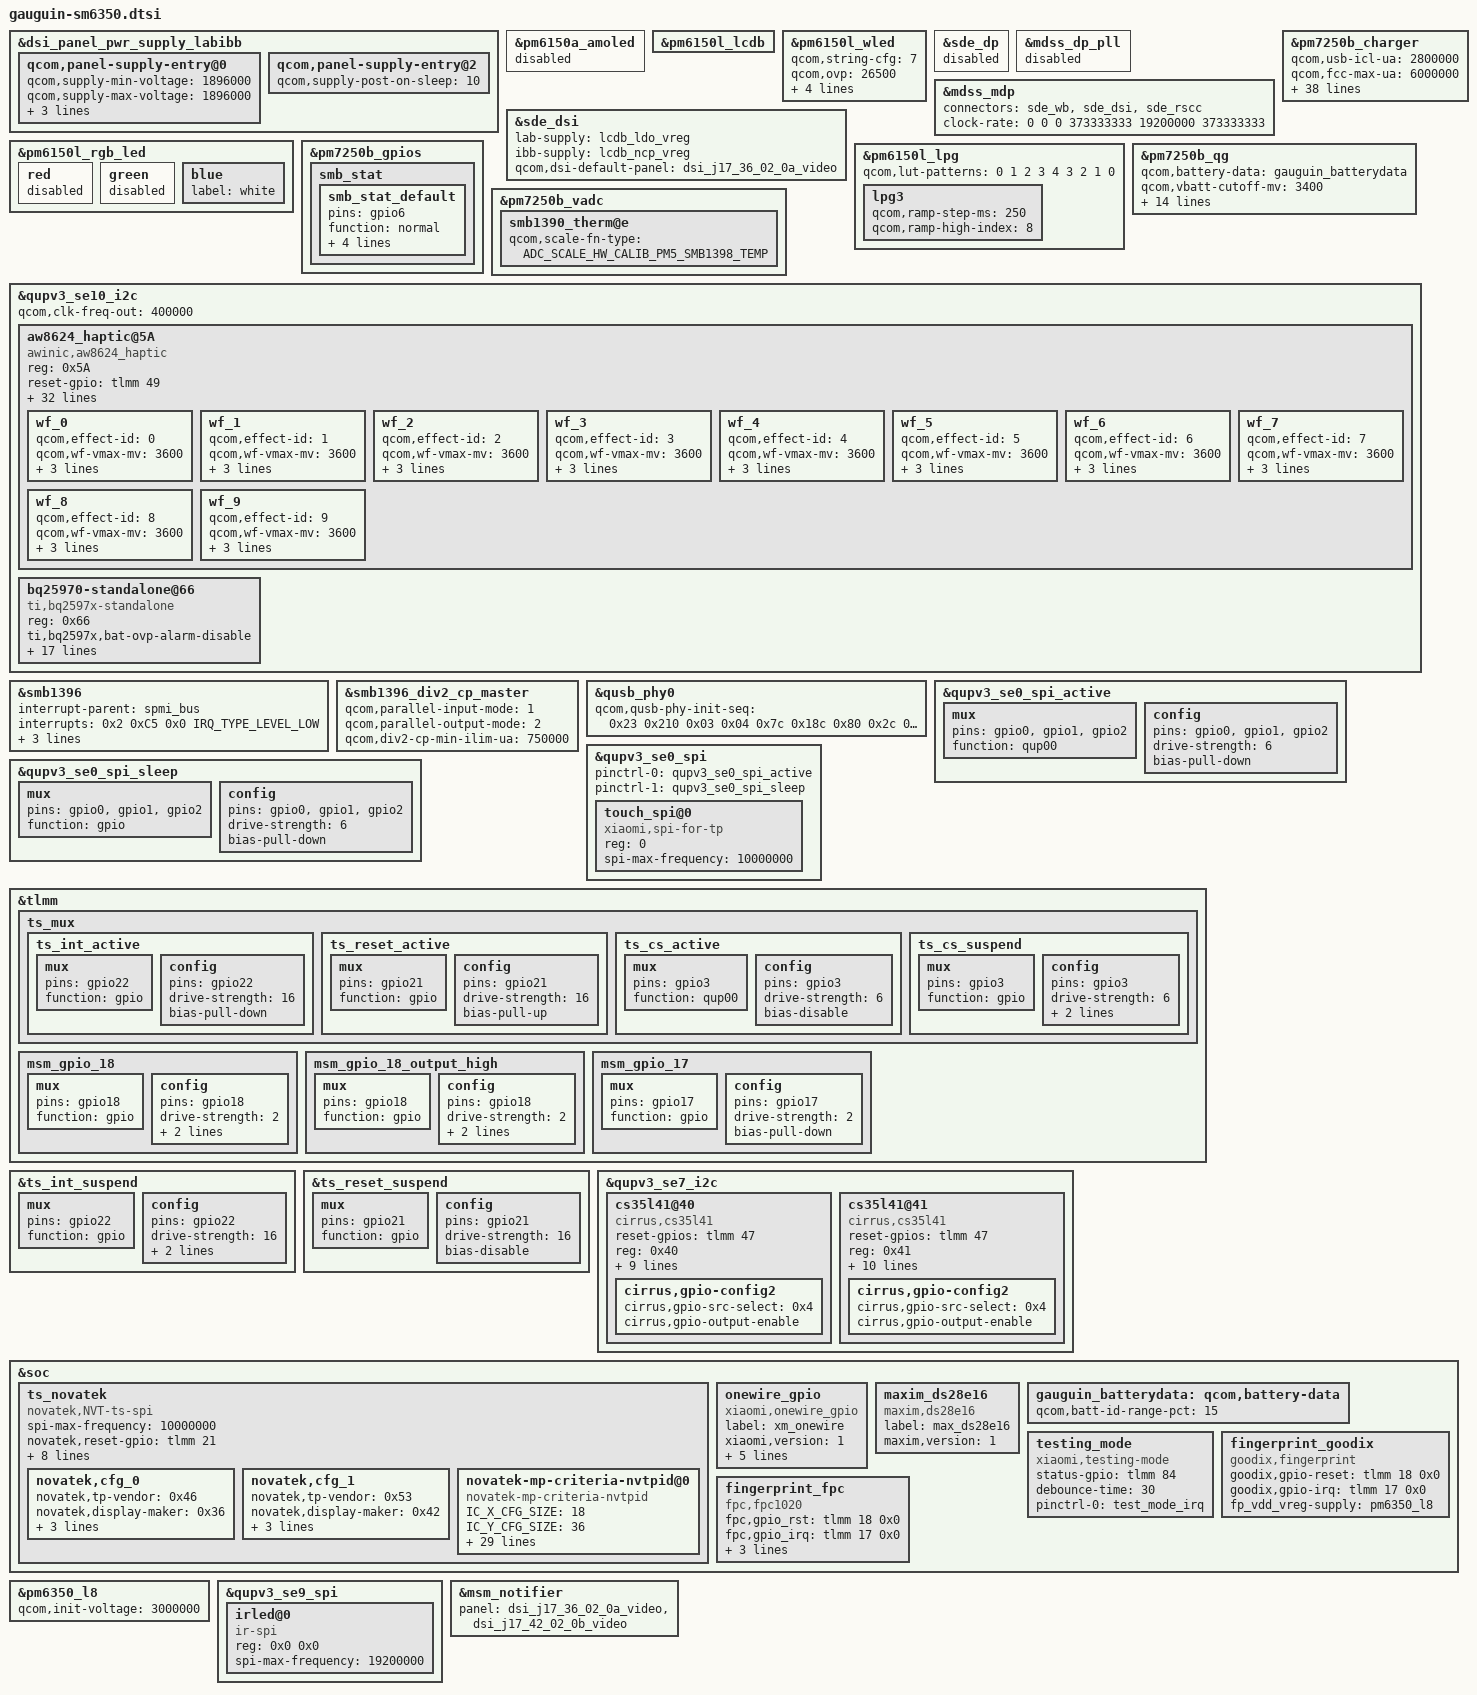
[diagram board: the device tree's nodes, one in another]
 /*
 file is for attribution only of gauguin
 And public attribution of xiaomi platforms(like J17 and so and)
 */

#include "gauguin-pinctrl.dtsi"
#include "xiaomi-sm6350-common.dtsi"
#include "gauguin-audio-overlay.dtsi"
#include <dt-bindings/pinctrl/qcom,pmic-gpio.h>
#include <dt-bindings/iio/qcom,spmi-vadc.h>

&dsi_panel_pwr_supply_labibb {
	qcom,panel-supply-entry@0 {
		qcom,supply-min-voltage = <1896000>;
		qcom,supply-max-voltage = <1896000>;
		qcom,supply-post-on-sleep = <1>;
		qcom,supply-post-off-sleep = <20>;
		qcom,supply-pre-off-sleep = <5>;
	};

	qcom,panel-supply-entry@2 {
		qcom,supply-post-on-sleep = <10>;
	};
};

&pm6150a_amoled {
	status = "disabled";
};

&pm6150l_lcdb {
	status = "ok";
	/delete-property/ qcom,voltage-step-ramp;
};

&pm6150l_wled {
	status = "ok";
	qcom,string-cfg = <7>;
	qcom,ovp = <26500>;
	qcom,fs-current-limit = <25000>;
	qcom,cabc-sel = <1>;
	mi,cabcoff-dbv = <200>;
	mi,cabc-pwm = <3111 4095>;
};

&sde_dp {
	status = "disabled";
};

&mdss_dp_pll {
	status = "disabled";
};

&mdss_mdp {
	connectors = <&sde_wb &sde_dsi &sde_rscc>;
	clock-rate = <0 0 0 373333333 19200000 373333333>;
};

&sde_dsi {
	/delete-property/ vdd-supply;
	lab-supply = <&lcdb_ldo_vreg>;
	ibb-supply = <&lcdb_ncp_vreg>;
	qcom,dsi-default-panel = <&dsi_j17_36_02_0a_video>;
};

&pm6150l_rgb_led {
	red {
		status = "disabled";
	};

	green {
		status = "disabled";
	};

	blue {
		label = "white";
	};
};

&pm6150l_lpg {
	qcom,lut-patterns = <0 1 2 3 4
				3 2 1 0>;
	lpg3 {
		qcom,ramp-step-ms = <250>;
		qcom,ramp-high-index = <8>;
	};
};

&pm7250b_charger {
	status = "ok";
	qcom,usb-icl-ua = <2800000>;
	qcom,fcc-max-ua = <6000000>;
	qcom,fv-max-uv = <4470000>;
	qcom,non-fcc-fv-max-uv = <4450000>;
	qcom,float-option = <1>;
	qcom,chg-term-src = <1>;
	qcom,chg-term-current-ma = <(-220)>;
	qcom,auto-recharge-soc = <99>;
	//qcom,step-charging-enable;
	qcom,sw-jeita-enable;
	qcom,lpd-disable;
	qcom,support-conn-therm;
	qcom,battery-data = <&gauguin_batterydata>;
	vbus-disable-gpio = <&tlmm 71 GPIO_ACTIVE_HIGH>;
	pinctrl-names = "default", "vbus_disable_active", "vbus_disable_suspend";
	pinctrl-0 = <&vbus_disable_suspend>;
	pinctrl-1 = <&vbus_disable_active>;
	pinctrl-2 = <&vbus_disable_suspend>;
	qcom,distinguish-qc-class-ab;
	mi,six-pin-step-chg-params = <4200000  6000000
				4400000  5400000
				4470000  3776000>;
	mi,six-pin-step-chg;
	mi,six-pin-soc-th = <10>;
	mi,support-ffc;
	qcom,thermal-mitigation = <3000000 2800000 2600000 2400000 2200000 2100000 2000000
			                           1800000 1600000 1500000 1400000 1200000 1000000 900000
			                           800000 500000>;
	qcom,thermal-mitigation-icl = <2800000 2700000 2600000 2400000 2200000 2100000 2000000
			                           1800000 1600000 1500000 1400000 1300000 1200000 1100000
			                           950000 750000>;
	qcom,thermal-mitigation-dcp = <3000000 2800000 2600000 2400000 2200000 2100000 2000000
			                           1800000 1600000 1500000 1400000 1200000 1000000 900000
			                           800000 500000>;
	qcom,thermal-mitigation-qc2 = <4800000 4600000 4400000 4100000 3900000 3600000 3000000
			                           2600000 2000000 1500000 1400000 1200000 1000000 900000
			                           800000 500000>;
	qcom,thermal-fcc-qc3p5 = <4500000 4400000 4200000 4100000 4000000 3800000 3600000
			                           3400000 3200000 3000000 2800000 2400000 2000000 1000000
			                           750000 750000>;
	qcom,thermal-fcc-qc3-cp = <3600000 3500000 3400000 3300000 3200000 3100000 3000000
			                           2900000 2800000 2600000 2400000 2200000 2000000 2000000
			                           750000 700000>;
	qcom,thermal-fcc-qc3-classb-cp = <5000000 4800000 4600000 4400000 4200000 4000000 3800000
			                           3600000 3400000 3200000 2500000 2200000 2000000 1300000
			                           1000000 700000>;
	qcom,thermal-mitigation-pd-base = <4800000 4500000 4200000 4100000 4000000 3800000 3600000
							3400000 3200000 3000000 2800000 2400000 2000000 1000000
							750000 750000>;
	qcom,thermal-fcc-pps = <6000000 5700000 5400000 5200000 4800000 4600000 4400000
							4200000 3800000 3400000 3000000 2600000 2000000 1000000
				   			700000 500000>;

};

&pm7250b_qg {
	qcom,battery-data = <&gauguin_batterydata>;
	qcom,vbatt-cutoff-mv = <3400>;
	qcom,vbatt-low-mv = <3300>;
	qcom,vbatt-empty-mv = <3100>;
	qcom,fvss-vbatt-mv = <3600>;
	qcom,s3-entry-fifo-length = <2>;
	qcom,s3-entry-ibat-ua = <25000>;
	qcom,s3-exit-ibat-ua = <45000>;
	qcom,qg-iterm-ma = <1200>;
	qcom,fvss-enable;
	qcom,qg-ext-sns;
	qcom,batterysecret-support;
	qcom,shutdown-delay-enable;
	qcom,soc_decimal_rate = <
		0  32
		10 30
		20 28
		30 28
		40 28
		50 28
		60 28
		70 28
		80 28
		90 26
		95 10
		99 5>;
	qcom,qg-fast-chg-config;
};

&pm7250b_gpios {
	smb_stat {
		smb_stat_default: smb_stat_default {
			pins = "gpio6";
			function = "normal";
			input-enable;
			bias-pull-up;
			qcom,pull-up-strength = <PMIC_GPIO_PULL_UP_30>;
			power-source = <0>;
		};
	};
};

&pm7250b_vadc {
	smb1390_therm@e {
		qcom,scale-fn-type = <ADC_SCALE_HW_CALIB_PM5_SMB1398_TEMP>;
	};
};

&qupv3_se10_i2c {
	status = "ok";
	qcom,clk-freq-out = <400000>;
	#include "smb1398.dtsi"
	aw8624_haptic@5A {
		compatible = "awinic,aw8624_haptic";
		reg = <0x5A>;
		reset-gpio = <&tlmm 49 0>;
		irq-gpio = <&tlmm 53 0>;
		vib_f0_pre = < 2050 >;
		vib_f0_cali_percen = < 7 >;
		vib_cont_drv_lev = < 106 >;
		vib_cont_drv_lvl_ov = < 155 >;
		vib_cont_td = < 0xF06C >;
		vib_cont_zc_thr = < 0x08F8 >;
		vib_cont_num_brk = < 3 >;
		vib_f0_coeff = < 260 >; /*Don't modify it*/
		vib_duration_time = < 15 60 0 0 0 >;
		vib_brake_ram_config = < 1 1 90 60 20 3 1 3 1 1 90 60 30 5 1 3 0 0 50 40 25 0 5 3 >;
		vib_brake_cont_config = < 1 1 90 42 20 5 2 2 0 0 0 0 0 0 0 0 0 0 0 0 0 0 0 0 >;
		vib_f0_trace_parameter = < 9 5 1 15 >;
		vib_bemf_config = < 0 8 3 0xf8 >;
		vib_sw_brake = < 0x2c >;
		vib_wavseq = < 0 1 1 2 0 0 0 0 0 0 0 0 0 0 0 0 >; /*wavseq1-seq8 0x07-0x0E*/
		vib_wavloop = < 0 6 1 15 0 0 0 0 0 0>;/*loop1-mainloog 0x0f-0x13*/
		vib_td_brake = < 42720 42720 42720 >; /*level0 level1 level2*/
		vib_tset = < 0x11 >;
		vib_func_parameter1 = < 1 >;
		vib_gain_flag = < 1 >;
		vib_r_spare = < 0x68 >;
		vib_bstdbg = < 0x30 0xeb 0xd4 0 0 0 >;
		vib_effect_id_boundary = < 10 >;
		vib_effect_max = < 170 >;
		vib_rtp_time = < 20 20 20 20 20 20 20 20 20 30
				 40 50 60 70 80 90 100 110 120 130
				 140 150 160 170 180 190 200 210 220 230
				 240 250 260 270 280 290 300 310 320 330
				 20 20 20 20 20 20 20 20 20 20
				 20 20 20 20 20 20 20 20 20 20
				 20 20 20 20 20 20 20 20 20 20
				 20 20 20 20 20 20 20 20 20 20
				 20 20 20 20 20 20 20 20 20 20
				 20 20 20 20 20 20 20 20 20 20
				 20 20 20 20 20 20 20 20 20 20
				 20 20 20 20 20 20 20 20 20 20
				 20 20 20 20 20 20 20 20 20 20
				 20 20 20 20 20 20 20 20 20 20
				 20 20 20 20 20 20 20 20 20 20
				 20 20 20 20 20 20 20 20 20 20
				 20 20 20 20 20 20 20 20 20 20
				 20 20 20 20 20 >;
		pinctrl-names = "aw8624_reset_reset","aw8624_reset_active","aw8624_interrupt_active";
		pinctrl-0 = <&aw8624_gpio_reset>;
		pinctrl-1 = <&aw8624_gpio_reset_output_high>;
		pinctrl-2 = <&aw8624_gpio_interrupt>;
		wf_0 {
			/*CLICK*/
			qcom,effect-id = <0>;
			qcom,wf-vmax-mv = <3600>;
			qcom,wf-pattern = [3e 3e];
			qcom,wf-brake-pattern = [02 01 00 00];
			qcom,wf-play-rate-us = <20000>;
		};
		wf_1 {
			/*DOUBLE CLICK*/
			qcom,effect-id = <1>;
			qcom,wf-vmax-mv = <3600>;
			qcom,wf-pattern = [7e 3e];
			qcom,wf-brake-pattern = [03 01 00 00];
			qcom,wf-play-rate-us = <20000>;
		};
		wf_2 {
			/*TICK*/
			qcom,effect-id = <2>;
			qcom,wf-vmax-mv = <3600>;
			qcom,wf-pattern = [7e 3e];
			qcom,wf-brake-pattern = [02 01 00 00];
			qcom,wf-play-rate-us = <20000>;
		};
		wf_3 {
			/*THUD*/
			qcom,effect-id = <3>;
			qcom,wf-vmax-mv = <3600>;
			qcom,wf-pattern = [3e 3e];
			qcom,wf-brake-pattern = [02 01 00 00];
			qcom,wf-play-rate-us = <20000>;
		};
		wf_4 {
			/*POP*/
			qcom,effect-id = <4>;
			qcom,wf-vmax-mv = <3600>;
			qcom,wf-pattern = [3e 3e];
			qcom,wf-brake-pattern = [02 01 00 00];
			qcom,wf-play-rate-us = <28000>;
		};
		wf_5 {
			/*HEAVY CLICK*/
			qcom,effect-id = <5>;
			qcom,wf-vmax-mv = <3600>;
			qcom,wf-pattern = [7e 7e 7e];
			qcom,wf-brake-pattern = [03 03 01 00];
			qcom,wf-play-rate-us = <20000>;
		};
		wf_6 {
			/*id 6*/
			qcom,effect-id = <6>;
			qcom,wf-vmax-mv = <3600>;
			qcom,wf-pattern = [3e 3e];
			qcom,wf-brake-pattern = [02 01 00 00];
			qcom,wf-play-rate-us = <20000>;
		};
		wf_7 {
			/*id 7*/
			qcom,effect-id = <7>;
			qcom,wf-vmax-mv = <3600>;
			qcom,wf-pattern = [3e 3e];
			qcom,wf-brake-pattern = [02 01 00 00];
			qcom,wf-play-rate-us = <20000>;
		};
		wf_8 {
			/*id 8*/
			qcom,effect-id = <8>;
			qcom,wf-vmax-mv = <3600>;
			qcom,wf-pattern = [3e 3e];
			qcom,wf-brake-pattern = [02 01 00 00];
			qcom,wf-play-rate-us = <20000>;
		};
		wf_9 {
			/*id 9*/
			qcom,effect-id = <9>;
			qcom,wf-vmax-mv = <3600>;
			qcom,wf-pattern = [3e 3e];
			qcom,wf-brake-pattern = [02 01 00 00];
			qcom,wf-play-rate-us = <20000>;
		};
	};
	/* AWINIC AW8624 Haptic End */

	bq25970-standalone@66 {
		compatible = "ti,bq2597x-standalone";
		reg = <0x66>;
		/*interrupt-parent = <&tlmm>;
		interrupts = <157 0x2002>;
		pinctrl-names = "default";
		pinctrl-0 = <&bq2597x_master_int_default>;*/

		/*ti,bq2597x,bat-ovp-disable;*/
		ti,bq2597x,bat-ovp-alarm-disable;
		ti,bq2597x,bat-ocp-disable;
		ti,bq2597x,bat-ocp-alarm-disable;
		ti,bq2597x,bat-ucp-alarm-disable;
		ti,bq2597x,bat-ucp-disable;

		/*ti,bq2597x,bus-ovp-alarm-disable;
		ti,bq2597x,bus-ocp-disable;
		ti,bq2597x,bus-ocp-alarm-disable;*/
		ti,bq2597x,bat-therm-disable;
		ti,bq2597x,bus-therm-disable;
		ti,bq2597x,die-therm-disable;

		ti,bq2597x,bat-ovp-threshold = <4525>;
		ti,bq2597x,bat-ovp-alarm-threshold = <4525>;
		//ti,bq2597x,bat-ocp-threshold = <8000>;
		//ti,bq2597x,bat-ocp-alarm-threshold = <7500>;

		ti,bq2597x,bus-ovp-threshold = <12000>;
		ti,bq2597x,bus-ovp-alarm-threshold = <11000>;
		ti,bq2597x,bus-ocp-threshold = <3750>;
		ti,bq2597x,bus-ocp-alarm-threshold = <3500>;

		//ti,bq2597x,bat-ucp-alarm-threshold = <2000>;

		ti,bq2597x,bat-therm-threshold = <0x15>;/*4.1%*/
		ti,bq2597x,bus-therm-threshold = <0x15>;/*4.1%*/
		ti,bq2597x,die-therm-threshold = <145>;

		ti,bq2597x,ac-ovp-threshold = <14>;
		//ti,bq2597x,sense-resistor-mohm = <2>;
	};
};

&smb1396 {
	interrupt-parent = <&spmi_bus>;
	interrupts = <0x2 0xC5 0x0 IRQ_TYPE_LEVEL_LOW>;
	interrupt_names = "smb1396";
	pinctrl-names = "default";
	pinctrl-0 = <&smb_stat_default>;
	qcom,enable-toggle-stat;
	status = "ok";
};

&smb1396_div2_cp_master {
	qcom,parallel-input-mode = <1>; /* USBIN */
	qcom,parallel-output-mode = <2>; /* VBAT */
	qcom,div2-cp-min-ilim-ua = <750000>;
	status = "ok";
};

&qusb_phy0 {
	qcom,qusb-phy-init-seq =
			/* <value reg_offset> */
			<0x23 0x210 /* PWR_CTRL1 */
			 0x03 0x04  /* PLL_ANALOG_CONTROLS_TWO */
			 0x7c 0x18c /* PLL_CLOCK_INVERTERS */
			 0x80 0x2c  /* PLL_CMODE */
			 0x0a 0x184 /* PLL_LOCK_DELAY */
			 0x19 0xb4  /* PLL_DIGITAL_TIMERS_TWO */
			 0x40 0x194 /* PLL_BIAS_CONTROL_1 */
			 0x17 0x198 /* PLL_BIAS_CONTROL_2 */
			 0x21 0x214 /* PWR_CTRL2 */
			 0x08 0x220 /* IMP_CTRL1 */
			 0x58 0x224 /* IMP_CTRL2 */
			 0x47 0x240 /* TUNE1 */
			 0x29 0x244 /* TUNE2 */
			 0xca 0x248 /* TUNE3 */
			 0x02 0x24c /* TUNE4 */
			 0x03 0x250 /* TUNE5 */
			 0x30 0x23c /* CHG_CTRL2 */
			 0x22 0x210>; /* PWR_CTRL1 */
};

/*Touch SPI state init*/
&qupv3_se0_spi_active {
	mux {
		pins = "gpio0", "gpio1", "gpio2";
		function = "qup00";
	};

	config {
		pins = "gpio0", "gpio1", "gpio2";
		drive-strength = <6>;
		bias-pull-down;
	};
};

&qupv3_se0_spi_sleep {
	mux {
		pins = "gpio0", "gpio1", "gpio2";
		function = "gpio";
	};

	config {
		pins = "gpio0", "gpio1", "gpio2";
		drive-strength = <6>;
		bias-pull-down;
	};
};

&qupv3_se0_spi {
	pinctrl-0 = <&qupv3_se0_spi_active>;
	pinctrl-1 = <&qupv3_se0_spi_sleep>;
};

/*IC int pin, rst pin init*/
&tlmm {
	ts_mux {
		ts_int_active: ts_int_active {
			mux {
				pins = "gpio22";
				function = "gpio";
			};

			config {
				pins = "gpio22";
				drive-strength = <16>;
				bias-pull-down;
			};
		};

		ts_reset_active: ts_reset_active {
			mux {
				pins = "gpio21";
				function = "gpio";
			};

			config {
				pins = "gpio21";
				drive-strength = <16>;
				bias-pull-up;
			};
		};

		ts_cs_active: ts_cs_active {
			mux {
				pins = "gpio3";
				function = "qup00";
			};

			config {
				pins = "gpio3";
				drive-strength = <6>;
				bias-disable;
			};
		};

		ts_cs_suspend: ts_cs_suspend {
			mux {
				pins = "gpio3";
				function = "gpio";
			};

			config {
				pins = "gpio3";
				drive-strength = <6>;
				bias-pull-down;
				output-low;
			};
		};
	};
};

&ts_int_suspend {
	mux {
		pins = "gpio22";
		function = "gpio";
	};

	config {
		pins = "gpio22";
		drive-strength = <16>;
		bias-disable;
		input-enable;
	};
};

&ts_reset_suspend {
	mux {
		pins = "gpio21";
		function = "gpio";
	};

	config {
		pins = "gpio21";
		drive-strength = <16>;
		bias-disable;
	};
};

&qupv3_se0_spi {
	status = "ok";
	touch_spi@0 {
		compatible = "xiaomi,spi-for-tp";
		reg = <0>;
		status = "ok";
		spi-max-frequency = <10000000>;  //10M
	};
};

&qupv3_se7_i2c {
	status = "ok";

	/* Speaker */
	cs35l41@40 {
		#sound-dai-cells = <1>;
		compatible = "cirrus,cs35l41";
		reset-gpios = <&tlmm 47 0>;
		reg = <0x40>;
		pinctrl-names = "cs35l41_irq_speaker";
		pinctrl-0 = <&cs35l41_int_speaker>;
		interrupt-parent = <&tlmm>;
		interrupts = <12 8>;
		cirrus,temp-warn_threshold = <3>;
		cirrus,boost-peak-milliamp = <4000>;
		cirrus,boost-ind-nanohenry = <1000>;
		cirrus,boost-cap-microfarad = <15>;
		cirrus,asp-sdout-hiz = <1>;
		cirrus,right-channel-amp;
		cirrus,gpio-config2 {
			cirrus,gpio-src-select = <0x4>;
			cirrus,gpio-output-enable;
		};
	};

	/* Receiver */
	cs35l41@41 {
		#sound-dai-cells = <1>;
		compatible = "cirrus,cs35l41";
		reset-gpios = <&tlmm 47 0>;
		reg = <0x41>;
		pinctrl-names = "cs35l41_irq_speaker_rcv";
		pinctrl-0 = <&cs35l41_int_speaker_rcv>;
		interrupt-parent = <&tlmm>;
		interrupts = <48 8>;
		cirrus,temp-warn_threshold = <3>;
		cirrus,boost-peak-milliamp = <4000>;
		cirrus,boost-ind-nanohenry = <1000>;
		cirrus,boost-cap-microfarad = <15>;
		//cirrus,right-channel-amp;
		cirrus,tuning-has-prefix;
		cirrus,asp-sdout-hiz = <1>;
		sound-name-prefix = "RCV";
		cirrus,gpio-config2 {
			cirrus,gpio-src-select = <0x4>;
			cirrus,gpio-output-enable;
		};
	};
};

/* Novatek device tree node */
&soc {
	ts_novatek {
		compatible = "novatek,NVT-ts-spi";
		status = "ok";
		spi-max-frequency = <10000000>;  /*4800000,9600000,15000000,19200000 10M*/
		novatek,reset-gpio = <&tlmm 21 0x00>;
		novatek,irq-gpio = <&tlmm 22 0x2001>;
		pinctrl-names = "pmx_ts_active", "pmx_ts_suspend";
		pinctrl-0 = <&ts_int_active &ts_reset_active &ts_cs_active>;
		pinctrl-1 = <&ts_int_suspend &ts_reset_suspend &ts_cs_suspend>;
		/* 672 */
		/*novatek,swrst-n8-addr = <0x01F01A>;*/
		/* 672A */
		novatek,swrst-n8-addr = <0x03F0FE>;
		novatek,spi-rd-fast-addr = <0x03F310>;
		novatek,config-array-size = <2>;
		novatek,cfg_0 {
			novatek,tp-vendor = <0x46>;
			novatek,display-maker = <0x36>;
			novatek,fw-name = "novatek_nt36672c_j17_fw01.bin";
			novatek,mp-name = "novatek_nt36672c_j17_mp01.bin";
			novatek,clicknum-file-name = "nvt+tianma";
		};
		novatek,cfg_1 {
			novatek,tp-vendor = <0x53>;
			novatek,display-maker = <0x42>;
			novatek,fw-name = "novatek_nt36672c_j17_fw02.bin";
			novatek,mp-name = "novatek_nt36672c_j17_mp02.bin";
			novatek,clicknum-file-name = "nvt+csot";
		};
		/* MP */
		/*novatek,mp-support-dt;*/
		novatek-mp-criteria-nvtpid@0 {
			#address-cells = <1>;
			#size-cells = <0>;
			compatible = "novatek-mp-criteria-nvtpid";
			/* MP Config */
			IC_X_CFG_SIZE = <18>;
			IC_Y_CFG_SIZE = <36>;
			IC_KEY_CFG_SIZE = <4>;
			X_Channel = <18>;
			Y_Channel = <36>;
			AIN_X = <0 1 2 3 4 5 6 7 8 9 10 11 12 13 14 15 16 17>;
			AIN_Y = <0 1 2 3 4 5 6 7 8 9 10 11 12 13 14 15 16 17
						18 19 20 21 22 23 24 25 26 27 28 29 30 31 32 33 34 35>;
			AIN_KEY = <0 1 2 0xFF>;
			/* MP Criteria */
			PS_Config_Lmt_Short_Rawdata_P = <
				14008 14008 14008 14008 14008 14008 14008 14008 14008 14008 14008 14008 14008 14008 14008 14008 14008 14008
				14008 14008 14008 14008 14008 14008 14008 14008 14008 14008 14008 14008 14008 14008 14008 14008 14008 14008
				14008 14008 14008 14008 14008 14008 14008 14008 14008 14008 14008 14008 14008 14008 14008 14008 14008 14008
				14008 14008 14008 14008 14008 14008 14008 14008 14008 14008 14008 14008 14008 14008 14008 14008 14008 14008
				14008 14008 14008 14008 14008 14008 14008 14008 14008 14008 14008 14008 14008 14008 14008 14008 14008 14008
				14008 14008 14008 14008 14008 14008 14008 14008 14008 14008 14008 14008 14008 14008 14008 14008 14008 14008
				14008 14008 14008 14008 14008 14008 14008 14008 14008 14008 14008 14008 14008 14008 14008 14008 14008 14008
				14008 14008 14008 14008 14008 14008 14008 14008 14008 14008 14008 14008 14008 14008 14008 14008 14008 14008
				14008 14008 14008 14008 14008 14008 14008 14008 14008 14008 14008 14008 14008 14008 14008 14008 14008 14008
				14008 14008 14008 14008 14008 14008 14008 14008 14008 14008 14008 14008 14008 14008 14008 14008 14008 14008
				14008 14008 14008 14008 14008 14008 14008 14008 14008 14008 14008 14008 14008 14008 14008 14008 14008 14008
				14008 14008 14008 14008 14008 14008 14008 14008 14008 14008 14008 14008 14008 14008 14008 14008 14008 14008
				14008 14008 14008 14008 14008 14008 14008 14008 14008 14008 14008 14008 14008 14008 14008 14008 14008 14008
				14008 14008 14008 14008 14008 14008 14008 14008 14008 14008 14008 14008 14008 14008 14008 14008 14008 14008
				14008 14008 14008 14008 14008 14008 14008 14008 14008 14008 14008 14008 14008 14008 14008 14008 14008 14008
				14008 14008 14008 14008 14008 14008 14008 14008 14008 14008 14008 14008 14008 14008 14008 14008 14008 14008
				14008 14008 14008 14008 14008 14008 14008 14008 14008 14008 14008 14008 14008 14008 14008 14008 14008 14008
				14008 14008 14008 14008 14008 14008 14008 14008 14008 14008 14008 14008 14008 14008 14008 14008 14008 14008
				14008 14008 14008 14008 14008 14008 14008 14008 14008 14008 14008 14008 14008 14008 14008 14008 14008 14008
				14008 14008 14008 14008 14008 14008 14008 14008 14008 14008 14008 14008 14008 14008 14008 14008 14008 14008
				14008 14008 14008 14008 14008 14008 14008 14008 14008 14008 14008 14008 14008 14008 14008 14008 14008 14008
				14008 14008 14008 14008 14008 14008 14008 14008 14008 14008 14008 14008 14008 14008 14008 14008 14008 14008
				14008 14008 14008 14008 14008 14008 14008 14008 14008 14008 14008 14008 14008 14008 14008 14008 14008 14008
				14008 14008 14008 14008 14008 14008 14008 14008 14008 14008 14008 14008 14008 14008 14008 14008 14008 14008
				14008 14008 14008 14008 14008 14008 14008 14008 14008 14008 14008 14008 14008 14008 14008 14008 14008 14008
				14008 14008 14008 14008 14008 14008 14008 14008 14008 14008 14008 14008 14008 14008 14008 14008 14008 14008
				14008 14008 14008 14008 14008 14008 14008 14008 14008 14008 14008 14008 14008 14008 14008 14008 14008 14008
				14008 14008 14008 14008 14008 14008 14008 14008 14008 14008 14008 14008 14008 14008 14008 14008 14008 14008
				14008 14008 14008 14008 14008 14008 14008 14008 14008 14008 14008 14008 14008 14008 14008 14008 14008 14008
				14008 14008 14008 14008 14008 14008 14008 14008 14008 14008 14008 14008 14008 14008 14008 14008 14008 14008
				14008 14008 14008 14008 14008 14008 14008 14008 14008 14008 14008 14008 14008 14008 14008 14008 14008 14008
				14008 14008 14008 14008 14008 14008 14008 14008 14008 14008 14008 14008 14008 14008 14008 14008 14008 14008
				14008 14008 14008 14008 14008 14008 14008 14008 14008 14008 14008 14008 14008 14008 14008 14008 14008 14008
				14008 14008 14008 14008 14008 14008 14008 14008 14008 14008 14008 14008 14008 14008 14008 14008 14008 14008
				14008 14008 14008 14008 14008 14008 14008 14008 14008 14008 14008 14008 14008 14008 14008 14008 14008 14008
				14008 14008 14008 14008 14008 14008 14008 14008 14008 14008 14008 14008 14008 14008 14008 14008 14008 14008
				14008 14008 14008>;

			PS_Config_Lmt_Short_Rawdata_N = <
				10000 10000 10000 10000 10000 10000 10000 10000 10000 10000 10000 10000 10000 10000 10000 10000 10000 10000
				10000 10000 10000 10000 10000 10000 10000 10000 10000 10000 10000 10000 10000 10000 10000 10000 10000 10000
				10000 10000 10000 10000 10000 10000 10000 10000 10000 10000 10000 10000 10000 10000 10000 10000 10000 10000
				10000 10000 10000 10000 10000 10000 10000 10000 10000 10000 10000 10000 10000 10000 10000 10000 10000 10000
				10000 10000 10000 10000 10000 10000 10000 10000 10000 10000 10000 10000 10000 10000 10000 10000 10000 10000
				10000 10000 10000 10000 10000 10000 10000 10000 10000 10000 10000 10000 10000 10000 10000 10000 10000 10000
				10000 10000 10000 10000 10000 10000 10000 10000 10000 10000 10000 10000 10000 10000 10000 10000 10000 10000
				10000 10000 10000 10000 10000 10000 10000 10000 10000 10000 10000 10000 10000 10000 10000 10000 10000 10000
				10000 10000 10000 10000 10000 10000 10000 10000 10000 10000 10000 10000 10000 10000 10000 10000 10000 10000
				10000 10000 10000 10000 10000 10000 10000 10000 10000 10000 10000 10000 10000 10000 10000 10000 10000 10000
				10000 10000 10000 10000 10000 10000 10000 10000 10000 10000 10000 10000 10000 10000 10000 10000 10000 10000
				10000 10000 10000 10000 10000 10000 10000 10000 10000 10000 10000 10000 10000 10000 10000 10000 10000 10000
				10000 10000 10000 10000 10000 10000 10000 10000 10000 10000 10000 10000 10000 10000 10000 10000 10000 10000
				10000 10000 10000 10000 10000 10000 10000 10000 10000 10000 10000 10000 10000 10000 10000 10000 10000 10000
				10000 10000 10000 10000 10000 10000 10000 10000 10000 10000 10000 10000 10000 10000 10000 10000 10000 10000
				10000 10000 10000 10000 10000 10000 10000 10000 10000 10000 10000 10000 10000 10000 10000 10000 10000 10000
				10000 10000 10000 10000 10000 10000 10000 10000 10000 10000 10000 10000 10000 10000 10000 10000 10000 10000
				10000 10000 10000 10000 10000 10000 10000 10000 10000 10000 10000 10000 10000 10000 10000 10000 10000 10000
				10000 10000 10000 10000 10000 10000 10000 10000 10000 10000 10000 10000 10000 10000 10000 10000 10000 10000
				10000 10000 10000 10000 10000 10000 10000 10000 10000 10000 10000 10000 10000 10000 10000 10000 10000 10000
				10000 10000 10000 10000 10000 10000 10000 10000 10000 10000 10000 10000 10000 10000 10000 10000 10000 10000
				10000 10000 10000 10000 10000 10000 10000 10000 10000 10000 10000 10000 10000 10000 10000 10000 10000 10000
				10000 10000 10000 10000 10000 10000 10000 10000 10000 10000 10000 10000 10000 10000 10000 10000 10000 10000
				10000 10000 10000 10000 10000 10000 10000 10000 10000 10000 10000 10000 10000 10000 10000 10000 10000 10000
				10000 10000 10000 10000 10000 10000 10000 10000 10000 10000 10000 10000 10000 10000 10000 10000 10000 10000
				10000 10000 10000 10000 10000 10000 10000 10000 10000 10000 10000 10000 10000 10000 10000 10000 10000 10000
				10000 10000 10000 10000 10000 10000 10000 10000 10000 10000 10000 10000 10000 10000 10000 10000 10000 10000
				10000 10000 10000 10000 10000 10000 10000 10000 10000 10000 10000 10000 10000 10000 10000 10000 10000 10000
				10000 10000 10000 10000 10000 10000 10000 10000 10000 10000 10000 10000 10000 10000 10000 10000 10000 10000
				10000 10000 10000 10000 10000 10000 10000 10000 10000 10000 10000 10000 10000 10000 10000 10000 10000 10000
				10000 10000 10000 10000 10000 10000 10000 10000 10000 10000 10000 10000 10000 10000 10000 10000 10000 10000
				10000 10000 10000 10000 10000 10000 10000 10000 10000 10000 10000 10000 10000 10000 10000 10000 10000 10000
				10000 10000 10000 10000 10000 10000 10000 10000 10000 10000 10000 10000 10000 10000 10000 10000 10000 10000
				10000 10000 10000 10000 10000 10000 10000 10000 10000 10000 10000 10000 10000 10000 10000 10000 10000 10000
				10000 10000 10000 10000 10000 10000 10000 10000 10000 10000 10000 10000 10000 10000 10000 10000 10000 10000
				10000 10000 10000 10000 10000 10000 10000 10000 10000 10000 10000 10000 10000 10000 10000 10000 10000 10000
				10000 10000 10000>;

			PS_Config_Lmt_Open_Rawdata_P = <
				4096 4096 4096 4096 4096 4096 4096 4096 4096 4096 4096 4096 4096 4096 4096 4096 4096 4096
				4096 4096 4096 4096 4096 4096 4096 4096 4096 4096 4096 4096 4096 4096 4096 4096 4096 4096
				4096 4096 4096 4096 4096 4096 4096 4096 4096 4096 4096 4096 4096 4096 4096 4096 4096 4096
				4096 4096 4096 4096 4096 4096 4096 4096 4096 4096 4096 4096 4096 4096 4096 4096 4096 4096
				4096 4096 4096 4096 4096 4096 4096 4096 4096 4096 4096 4096 4096 4096 4096 4096 4096 4096
				4096 4096 4096 4096 4096 4096 4096 4096 4096 4096 4096 4096 4096 4096 4096 4096 4096 4096
				4096 4096 4096 4096 4096 4096 4096 4096 4096 4096 4096 4096 4096 4096 4096 4096 4096 4096
				4096 4096 4096 4096 4096 4096 4096 4096 4096 4096 4096 4096 4096 4096 4096 4096 4096 4096
				4096 4096 4096 4096 4096 4096 4096 4096 4096 4096 4096 4096 4096 4096 4096 4096 4096 4096
				4096 4096 4096 4096 4096 4096 4096 4096 4096 4096 4096 4096 4096 4096 4096 4096 4096 4096
				4096 4096 4096 4096 4096 4096 4096 4096 4096 4096 4096 4096 4096 4096 4096 4096 4096 4096
				4096 4096 4096 4096 4096 4096 4096 4096 4096 4096 4096 4096 4096 4096 4096 4096 4096 4096
				4096 4096 4096 4096 4096 4096 4096 4096 4096 4096 4096 4096 4096 4096 4096 4096 4096 4096
				4096 4096 4096 4096 4096 4096 4096 4096 4096 4096 4096 4096 4096 4096 4096 4096 4096 4096
				4096 4096 4096 4096 4096 4096 4096 4096 4096 4096 4096 4096 4096 4096 4096 4096 4096 4096
				4096 4096 4096 4096 4096 4096 4096 4096 4096 4096 4096 4096 4096 4096 4096 4096 4096 4096
				4096 4096 4096 4096 4096 4096 4096 4096 4096 4096 4096 4096 4096 4096 4096 4096 4096 4096
				4096 4096 4096 4096 4096 4096 4096 4096 4096 4096 4096 4096 4096 4096 4096 4096 4096 4096
				4096 4096 4096 4096 4096 4096 4096 4096 4096 4096 4096 4096 4096 4096 4096 4096 4096 4096
				4096 4096 4096 4096 4096 4096 4096 4096 4096 4096 4096 4096 4096 4096 4096 4096 4096 4096
				4096 4096 4096 4096 4096 4096 4096 4096 4096 4096 4096 4096 4096 4096 4096 4096 4096 4096
				4096 4096 4096 4096 4096 4096 4096 4096 4096 4096 4096 4096 4096 4096 4096 4096 4096 4096
				4096 4096 4096 4096 4096 4096 4096 4096 4096 4096 4096 4096 4096 4096 4096 4096 4096 4096
				4096 4096 4096 4096 4096 4096 4096 4096 4096 4096 4096 4096 4096 4096 4096 4096 4096 4096
				4096 4096 4096 4096 4096 4096 4096 4096 4096 4096 4096 4096 4096 4096 4096 4096 4096 4096
				4096 4096 4096 4096 4096 4096 4096 4096 4096 4096 4096 4096 4096 4096 4096 4096 4096 4096
				4096 4096 4096 4096 4096 4096 4096 4096 4096 4096 4096 4096 4096 4096 4096 4096 4096 4096
				4096 4096 4096 4096 4096 4096 4096 4096 4096 4096 4096 4096 4096 4096 4096 4096 4096 4096
				4096 4096 4096 4096 4096 4096 4096 4096 4096 4096 4096 4096 4096 4096 4096 4096 4096 4096
				4096 4096 4096 4096 4096 4096 4096 4096 4096 4096 4096 4096 4096 4096 4096 4096 4096 4096
				4096 4096 4096 4096 4096 4096 4096 4096 4096 4096 4096 4096 4096 4096 4096 4096 4096 4096
				4096 4096 4096 4096 4096 4096 4096 4096 4096 4096 4096 4096 4096 4096 4096 4096 4096 4096
				4096 4096 4096 4096 4096 4096 4096 4096 4096 4096 4096 4096 4096 4096 4096 4096 4096 4096
				4096 4096 4096 4096 4096 4096 4096 4096 4096 4096 4096 4096 4096 4096 4096 4096 4096 4096
				4096 4096 4096 4096 4096 4096 4096 4096 4096 4096 4096 4096 4096 4096 4096 4096 4096 4096
				4096 4096 4096 4096 4096 4096 4096 4096 4096 4096 4096 4096 4096 4096 4096 4096 4096 4096
				4096 4096 4096>;

			PS_Config_Lmt_Open_Rawdata_N = <
				50 50 50 50 50 50 50 50 50 50 50 50 50 50 50 50 50 50
				50 50 50 50 50 50 50 50 50 50 50 50 50 50 50 50 50 50
				50 50 50 50 50 50 50 50 50 50 50 50 50 50 50 50 50 50
				50 50 50 50 50 50 50 50 50 50 50 50 50 50 50 50 50 50
				50 50 50 50 50 50 50 50 50 50 50 50 50 50 50 50 50 50
				50 50 50 50 50 50 50 50 50 50 50 50 50 50 50 50 50 50
				50 50 50 50 50 50 50 50 50 50 50 50 50 50 50 50 50 50
				50 50 50 50 50 50 50 50 50 50 50 50 50 50 50 50 50 50
				50 50 50 50 50 50 50 50 50 50 50 50 50 50 50 50 50 50
				50 50 50 50 50 50 50 50 50 50 50 50 50 50 50 50 50 50
				50 50 50 50 50 50 50 50 50 50 50 50 50 50 50 50 50 50
				50 50 50 50 50 50 50 50 50 50 50 50 50 50 50 50 50 50
				50 50 50 50 50 50 50 50 50 50 50 50 50 50 50 50 50 50
				50 50 50 50 50 50 50 50 50 50 50 50 50 50 50 50 50 50
				50 50 50 50 50 50 50 50 50 50 50 50 50 50 50 50 50 50
				50 50 50 50 50 50 50 50 50 50 50 50 50 50 50 50 50 50
				50 50 50 50 50 50 50 50 50 50 50 50 50 50 50 50 50 50
				50 50 50 50 50 50 50 50 50 50 50 50 50 50 50 50 50 50
				50 50 50 50 50 50 50 50 50 50 50 50 50 50 50 50 50 50
				50 50 50 50 50 50 50 50 50 50 50 50 50 50 50 50 50 50
				50 50 50 50 50 50 50 50 50 50 50 50 50 50 50 50 50 50
				50 50 50 50 50 50 50 50 50 50 50 50 50 50 50 50 50 50
				50 50 50 50 50 50 50 50 50 50 50 50 50 50 50 50 50 50
				50 50 50 50 50 50 50 50 50 50 50 50 50 50 50 50 50 50
				50 50 50 50 50 50 50 50 50 50 50 50 50 50 50 50 50 50
				50 50 50 50 50 50 50 50 50 50 50 50 50 50 50 50 50 50
				50 50 50 50 50 50 50 50 50 50 50 50 50 50 50 50 50 50
				50 50 50 50 50 50 50 50 50 50 50 50 50 50 50 50 50 50
				50 50 50 50 50 50 50 50 50 50 50 50 50 50 50 50 50 50
				50 50 50 50 50 50 50 50 50 50 50 50 50 50 50 50 50 50
				50 50 50 50 50 50 50 50 50 50 50 50 50 50 50 50 50 50
				50 50 50 50 50 50 50 50 50 50 50 50 50 50 50 50 50 50
				50 50 50 50 50 50 50 50 50 50 50 50 50 50 50 50 50 50
				50 50 50 50 50 50 50 50 50 50 50 50 50 50 50 50 50 50
				50 50 50 50 50 50 50 50 50 50 50 50 50 50 50 50 50 50
				50 50 50 50 50 50 50 50 50 50 50 50 50 50 50 50 50 50
				50 50 50>;

			PS_Config_Lmt_FW_Rawdata_P = <
				1920 1920 1920 1920 1920 1920 1920 1920 1920 1920 1920 1920 1920 1920 1920 1920 1920 1920
				1920 1920 1920 1920 1920 1920 1920 1920 1920 1920 1920 1920 1920 1920 1920 1920 1920 1920
				1920 1920 1920 1920 1920 1920 1920 1920 1920 1920 1920 1920 1920 1920 1920 1920 1920 1920
				1920 1920 1920 1920 1920 1920 1920 1920 1920 1920 1920 1920 1920 1920 1920 1920 1920 1920
				1920 1920 1920 1920 1920 1920 1920 1920 1920 1920 1920 1920 1920 1920 1920 1920 1920 1920
				1920 1920 1920 1920 1920 1920 1920 1920 1920 1920 1920 1920 1920 1920 1920 1920 1920 1920
				1920 1920 1920 1920 1920 1920 1920 1920 1920 1920 1920 1920 1920 1920 1920 1920 1920 1920
				1920 1920 1920 1920 1920 1920 1920 1920 1920 1920 1920 1920 1920 1920 1920 1920 1920 1920
				1920 1920 1920 1920 1920 1920 1920 1920 1920 1920 1920 1920 1920 1920 1920 1920 1920 1920
				1920 1920 1920 1920 1920 1920 1920 1920 1920 1920 1920 1920 1920 1920 1920 1920 1920 1920
				1920 1920 1920 1920 1920 1920 1920 1920 1920 1920 1920 1920 1920 1920 1920 1920 1920 1920
				1920 1920 1920 1920 1920 1920 1920 1920 1920 1920 1920 1920 1920 1920 1920 1920 1920 1920
				1920 1920 1920 1920 1920 1920 1920 1920 1920 1920 1920 1920 1920 1920 1920 1920 1920 1920
				1920 1920 1920 1920 1920 1920 1920 1920 1920 1920 1920 1920 1920 1920 1920 1920 1920 1920
				1920 1920 1920 1920 1920 1920 1920 1920 1920 1920 1920 1920 1920 1920 1920 1920 1920 1920
				1920 1920 1920 1920 1920 1920 1920 1920 1920 1920 1920 1920 1920 1920 1920 1920 1920 1920
				1920 1920 1920 1920 1920 1920 1920 1920 1920 1920 1920 1920 1920 1920 1920 1920 1920 1920
				1920 1920 1920 1920 1920 1920 1920 1920 1920 1920 1920 1920 1920 1920 1920 1920 1920 1920
				1920 1920 1920 1920 1920 1920 1920 1920 1920 1920 1920 1920 1920 1920 1920 1920 1920 1920
				1920 1920 1920 1920 1920 1920 1920 1920 1920 1920 1920 1920 1920 1920 1920 1920 1920 1920
				1920 1920 1920 1920 1920 1920 1920 1920 1920 1920 1920 1920 1920 1920 1920 1920 1920 1920
				1920 1920 1920 1920 1920 1920 1920 1920 1920 1920 1920 1920 1920 1920 1920 1920 1920 1920
				1920 1920 1920 1920 1920 1920 1920 1920 1920 1920 1920 1920 1920 1920 1920 1920 1920 1920
				1920 1920 1920 1920 1920 1920 1920 1920 1920 1920 1920 1920 1920 1920 1920 1920 1920 1920
				1920 1920 1920 1920 1920 1920 1920 1920 1920 1920 1920 1920 1920 1920 1920 1920 1920 1920
				1920 1920 1920 1920 1920 1920 1920 1920 1920 1920 1920 1920 1920 1920 1920 1920 1920 1920
				1920 1920 1920 1920 1920 1920 1920 1920 1920 1920 1920 1920 1920 1920 1920 1920 1920 1920
				1920 1920 1920 1920 1920 1920 1920 1920 1920 1920 1920 1920 1920 1920 1920 1920 1920 1920
				1920 1920 1920 1920 1920 1920 1920 1920 1920 1920 1920 1920 1920 1920 1920 1920 1920 1920
				1920 1920 1920 1920 1920 1920 1920 1920 1920 1920 1920 1920 1920 1920 1920 1920 1920 1920
				1920 1920 1920 1920 1920 1920 1920 1920 1920 1920 1920 1920 1920 1920 1920 1920 1920 1920
				1920 1920 1920 1920 1920 1920 1920 1920 1920 1920 1920 1920 1920 1920 1920 1920 1920 1920
				1920 1920 1920 1920 1920 1920 1920 1920 1920 1920 1920 1920 1920 1920 1920 1920 1920 1920
				1920 1920 1920 1920 1920 1920 1920 1920 1920 1920 1920 1920 1920 1920 1920 1920 1920 1920
				1920 1920 1920 1920 1920 1920 1920 1920 1920 1920 1920 1920 1920 1920 1920 1920 1920 1920
				1920 1920 1920 1920 1920 1920 1920 1920 1920 1920 1920 1920 1920 1920 1920 1920 1920 1920
				1920 1920 1920>;

			PS_Config_Lmt_FW_Rawdata_N = <
				240 240 240 240 240 240 240 240 240 240 240 240 240 240 240 240 240 240
				240 240 240 240 240 240 240 240 240 240 240 240 240 240 240 240 240 240
				240 240 240 240 240 240 240 240 240 240 240 240 240 240 240 240 240 240
				240 240 240 240 240 240 240 240 240 240 240 240 240 240 240 240 240 240
				240 240 240 240 240 240 240 240 240 240 240 240 240 240 240 240 240 240
				240 240 240 240 240 240 240 240 240 240 240 240 240 240 240 240 240 240
				240 240 240 240 240 240 240 240 240 240 240 240 240 240 240 240 240 240
				240 240 240 240 240 240 240 240 240 240 240 240 240 240 240 240 240 240
				240 240 240 240 240 240 240 240 240 240 240 240 240 240 240 240 240 240
				240 240 240 240 240 240 240 240 240 240 240 240 240 240 240 240 240 240
				240 240 240 240 240 240 240 240 240 240 240 240 240 240 240 240 240 240
				240 240 240 240 240 240 240 240 240 240 240 240 240 240 240 240 240 240
				240 240 240 240 240 240 240 240 240 240 240 240 240 240 240 240 240 240
				240 240 240 240 240 240 240 240 240 240 240 240 240 240 240 240 240 240
				240 240 240 240 240 240 240 240 240 240 240 240 240 240 240 240 240 240
				240 240 240 240 240 240 240 240 240 240 240 240 240 240 240 240 240 240
				240 240 240 240 240 240 240 240 240 240 240 240 240 240 240 240 240 240
				240 240 240 240 240 240 240 240 240 240 240 240 240 240 240 240 240 240
				240 240 240 240 240 240 240 240 240 240 240 240 240 240 240 240 240 240
				240 240 240 240 240 240 240 240 240 240 240 240 240 240 240 240 240 240
				240 240 240 240 240 240 240 240 240 240 240 240 240 240 240 240 240 240
				240 240 240 240 240 240 240 240 240 240 240 240 240 240 240 240 240 240
				240 240 240 240 240 240 240 240 240 240 240 240 240 240 240 240 240 240
				240 240 240 240 240 240 240 240 240 240 240 240 240 240 240 240 240 240
				240 240 240 240 240 240 240 240 240 240 240 240 240 240 240 240 240 240
				240 240 240 240 240 240 240 240 240 240 240 240 240 240 240 240 240 240
				240 240 240 240 240 240 240 240 240 240 240 240 240 240 240 240 240 240
				240 240 240 240 240 240 240 240 240 240 240 240 240 240 240 240 240 240
				240 240 240 240 240 240 240 240 240 240 240 240 240 240 240 240 240 240
				240 240 240 240 240 240 240 240 240 240 240 240 240 240 240 240 240 240
				240 240 240 240 240 240 240 240 240 240 240 240 240 240 240 240 240 240
				240 240 240 240 240 240 240 240 240 240 240 240 240 240 240 240 240 240
				240 240 240 240 240 240 240 240 240 240 240 240 240 240 240 240 240 240
				240 240 240 240 240 240 240 240 240 240 240 240 240 240 240 240 240 240
				240 240 240 240 240 240 240 240 240 240 240 240 240 240 240 240 240 240
				240 240 240 240 240 240 240 240 240 240 240 240 240 240 240 240 240 240
				240 240 240>;

			PS_Config_Lmt_FW_CC_P = <
				314 314 314 314 314 314 314 314 314 314 314 314 314 314 314 314 314 314
				314 314 314 314 314 314 314 314 314 314 314 314 314 314 314 314 314 314
				314 314 314 314 314 314 314 314 314 314 314 314 314 314 314 314 314 314
				314 314 314 314 314 314 314 314 314 314 314 314 314 314 314 314 314 314
				314 314 314 314 314 314 314 314 314 314 314 314 314 314 314 314 314 314
				314 314 314 314 314 314 314 314 314 314 314 314 314 314 314 314 314 314
				314 314 314 314 314 314 314 314 314 314 314 314 314 314 314 314 314 314
				314 314 314 314 314 314 314 314 314 314 314 314 314 314 314 314 314 314
				314 314 314 314 314 314 314 314 314 314 314 314 314 314 314 314 314 314
				314 314 314 314 314 314 314 314 314 314 314 314 314 314 314 314 314 314
				314 314 314 314 314 314 314 314 314 314 314 314 314 314 314 314 314 314
				314 314 314 314 314 314 314 314 314 314 314 314 314 314 314 314 314 314
				314 314 314 314 314 314 314 314 314 314 314 314 314 314 314 314 314 314
				314 314 314 314 314 314 314 314 314 314 314 314 314 314 314 314 314 314
				314 314 314 314 314 314 314 314 314 314 314 314 314 314 314 314 314 314
				314 314 314 314 314 314 314 314 314 314 314 314 314 314 314 314 314 314
				314 314 314 314 314 314 314 314 314 314 314 314 314 314 314 314 314 314
				314 314 314 314 314 314 314 314 314 314 314 314 314 314 314 314 314 314
				314 314 314 314 314 314 314 314 314 314 314 314 314 314 314 314 314 314
				314 314 314 314 314 314 314 314 314 314 314 314 314 314 314 314 314 314
				314 314 314 314 314 314 314 314 314 314 314 314 314 314 314 314 314 314
				314 314 314 314 314 314 314 314 314 314 314 314 314 314 314 314 314 314
				314 314 314 314 314 314 314 314 314 314 314 314 314 314 314 314 314 314
				314 314 314 314 314 314 314 314 314 314 314 314 314 314 314 314 314 314
				314 314 314 314 314 314 314 314 314 314 314 314 314 314 314 314 314 314
				314 314 314 314 314 314 314 314 314 314 314 314 314 314 314 314 314 314
				314 314 314 314 314 314 314 314 314 314 314 314 314 314 314 314 314 314
				314 314 314 314 314 314 314 314 314 314 314 314 314 314 314 314 314 314
				314 314 314 314 314 314 314 314 314 314 314 314 314 314 314 314 314 314
				314 314 314 314 314 314 314 314 314 314 314 314 314 314 314 314 314 314
				314 314 314 314 314 314 314 314 314 314 314 314 314 314 314 314 314 314
				314 314 314 314 314 314 314 314 314 314 314 314 314 314 314 314 314 314
				314 314 314 314 314 314 314 314 314 314 314 314 314 314 314 314 314 314
				314 314 314 314 314 314 314 314 314 314 314 314 314 314 314 314 314 314
				314 314 314 314 314 314 314 314 314 314 314 314 314 314 314 314 314 314
				314 314 314 314 314 314 314 314 314 314 314 314 314 314 314 314 314 314
				314 314 314>;

			PS_Config_Lmt_FW_CC_N = <
				30 30 30 30 30 30 30 30 30 30 30 30 30 30 30 30 30 30
				30 30 30 30 30 30 30 30 30 30 30 30 30 30 30 30 30 30
				30 30 30 30 30 30 30 30 30 30 30 30 30 30 30 30 30 30
				30 30 30 30 30 30 30 30 30 30 30 30 30 30 30 30 30 30
				30 30 30 30 30 30 30 30 30 30 30 30 30 30 30 30 30 30
				30 30 30 30 30 30 30 30 30 30 30 30 30 30 30 30 30 30
				30 30 30 30 30 30 30 30 30 30 30 30 30 30 30 30 30 30
				30 30 30 30 30 30 30 30 30 30 30 30 30 30 30 30 30 30
				30 30 30 30 30 30 30 30 30 30 30 30 30 30 30 30 30 30
				30 30 30 30 30 30 30 30 30 30 30 30 30 30 30 30 30 30
				30 30 30 30 30 30 30 30 30 30 30 30 30 30 30 30 30 30
				30 30 30 30 30 30 30 30 30 30 30 30 30 30 30 30 30 30
				30 30 30 30 30 30 30 30 30 30 30 30 30 30 30 30 30 30
				30 30 30 30 30 30 30 30 30 30 30 30 30 30 30 30 30 30
				30 30 30 30 30 30 30 30 30 30 30 30 30 30 30 30 30 30
				30 30 30 30 30 30 30 30 30 30 30 30 30 30 30 30 30 30
				30 30 30 30 30 30 30 30 30 30 30 30 30 30 30 30 30 30
				30 30 30 30 30 30 30 30 30 30 30 30 30 30 30 30 30 30
				30 30 30 30 30 30 30 30 30 30 30 30 30 30 30 30 30 30
				30 30 30 30 30 30 30 30 30 30 30 30 30 30 30 30 30 30
				30 30 30 30 30 30 30 30 30 30 30 30 30 30 30 30 30 30
				30 30 30 30 30 30 30 30 30 30 30 30 30 30 30 30 30 30
				30 30 30 30 30 30 30 30 30 30 30 30 30 30 30 30 30 30
				30 30 30 30 30 30 30 30 30 30 30 30 30 30 30 30 30 30
				30 30 30 30 30 30 30 30 30 30 30 30 30 30 30 30 30 30
				30 30 30 30 30 30 30 30 30 30 30 30 30 30 30 30 30 30
				30 30 30 30 30 30 30 30 30 30 30 30 30 30 30 30 30 30
				30 30 30 30 30 30 30 30 30 30 30 30 30 30 30 30 30 30
				30 30 30 30 30 30 30 30 30 30 30 30 30 30 30 30 30 30
				30 30 30 30 30 30 30 30 30 30 30 30 30 30 30 30 30 30
				30 30 30 30 30 30 30 30 30 30 30 30 30 30 30 30 30 30
				30 30 30 30 30 30 30 30 30 30 30 30 30 30 30 30 30 30
				30 30 30 30 30 30 30 30 30 30 30 30 30 30 30 30 30 30
				30 30 30 30 30 30 30 30 30 30 30 30 30 30 30 30 30 30
				30 30 30 30 30 30 30 30 30 30 30 30 30 30 30 30 30 30
				30 30 30 30 30 30 30 30 30 30 30 30 30 30 30 30 30 30
				30 30 30>;

			PS_Config_Lmt_FW_Diff_P = <
				75 75 75 75 75 75 75 75 75 75 75 75 75 75 75 75 75 75
				75 75 75 75 75 75 75 75 75 75 75 75 75 75 75 75 75 75
				75 75 75 75 75 75 75 75 75 75 75 75 75 75 75 75 75 75
				75 75 75 75 75 75 75 75 75 75 75 75 75 75 75 75 75 75
				75 75 75 75 75 75 75 75 75 75 75 75 75 75 75 75 75 75
				75 75 75 75 75 75 75 75 75 75 75 75 75 75 75 75 75 75
				75 75 75 75 75 75 75 75 75 75 75 75 75 75 75 75 75 75
				75 75 75 75 75 75 75 75 75 75 75 75 75 75 75 75 75 75
				75 75 75 75 75 75 75 75 75 75 75 75 75 75 75 75 75 75
				75 75 75 75 75 75 75 75 75 75 75 75 75 75 75 75 75 75
				75 75 75 75 75 75 75 75 75 75 75 75 75 75 75 75 75 75
				75 75 75 75 75 75 75 75 75 75 75 75 75 75 75 75 75 75
				75 75 75 75 75 75 75 75 75 75 75 75 75 75 75 75 75 75
				75 75 75 75 75 75 75 75 75 75 75 75 75 75 75 75 75 75
				75 75 75 75 75 75 75 75 75 75 75 75 75 75 75 75 75 75
				75 75 75 75 75 75 75 75 75 75 75 75 75 75 75 75 75 75
				75 75 75 75 75 75 75 75 75 75 75 75 75 75 75 75 75 75
				75 75 75 75 75 75 75 75 75 75 75 75 75 75 75 75 75 75
				75 75 75 75 75 75 75 75 75 75 75 75 75 75 75 75 75 75
				75 75 75 75 75 75 75 75 75 75 75 75 75 75 75 75 75 75
				75 75 75 75 75 75 75 75 75 75 75 75 75 75 75 75 75 75
				75 75 75 75 75 75 75 75 75 75 75 75 75 75 75 75 75 75
				75 75 75 75 75 75 75 75 75 75 75 75 75 75 75 75 75 75
				75 75 75 75 75 75 75 75 75 75 75 75 75 75 75 75 75 75
				75 75 75 75 75 75 75 75 75 75 75 75 75 75 75 75 75 75
				75 75 75 75 75 75 75 75 75 75 75 75 75 75 75 75 75 75
				75 75 75 75 75 75 75 75 75 75 75 75 75 75 75 75 75 75
				75 75 75 75 75 75 75 75 75 75 75 75 75 75 75 75 75 75
				75 75 75 75 75 75 75 75 75 75 75 75 75 75 75 75 75 75
				75 75 75 75 75 75 75 75 75 75 75 75 75 75 75 75 75 75
				75 75 75 75 75 75 75 75 75 75 75 75 75 75 75 75 75 75
				75 75 75 75 75 75 75 75 75 75 75 75 75 75 75 75 75 75
				75 75 75 75 75 75 75 75 75 75 75 75 75 75 75 75 75 75
				75 75 75 75 75 75 75 75 75 75 75 75 75 75 75 75 75 75
				75 75 75 75 75 75 75 75 75 75 75 75 75 75 75 75 75 75
				75 75 75 75 75 75 75 75 75 75 75 75 75 75 75 75 75 75
				75 75 75>;

			PS_Config_Lmt_FW_Diff_N = <
				(-75) (-75) (-75) (-75) (-75) (-75) (-75) (-75) (-75) (-75) (-75) (-75) (-75) (-75) (-75) (-75) (-75) (-75)
				(-75) (-75) (-75) (-75) (-75) (-75) (-75) (-75) (-75) (-75) (-75) (-75) (-75) (-75) (-75) (-75) (-75) (-75)
				(-75) (-75) (-75) (-75) (-75) (-75) (-75) (-75) (-75) (-75) (-75) (-75) (-75) (-75) (-75) (-75) (-75) (-75)
				(-75) (-75) (-75) (-75) (-75) (-75) (-75) (-75) (-75) (-75) (-75) (-75) (-75) (-75) (-75) (-75) (-75) (-75)
				(-75) (-75) (-75) (-75) (-75) (-75) (-75) (-75) (-75) (-75) (-75) (-75) (-75) (-75) (-75) (-75) (-75) (-75)
				(-75) (-75) (-75) (-75) (-75) (-75) (-75) (-75) (-75) (-75) (-75) (-75) (-75) (-75) (-75) (-75) (-75) (-75)
				(-75) (-75) (-75) (-75) (-75) (-75) (-75) (-75) (-75) (-75) (-75) (-75) (-75) (-75) (-75) (-75) (-75) (-75)
				(-75) (-75) (-75) (-75) (-75) (-75) (-75) (-75) (-75) (-75) (-75) (-75) (-75) (-75) (-75) (-75) (-75) (-75)
				(-75) (-75) (-75) (-75) (-75) (-75) (-75) (-75) (-75) (-75) (-75) (-75) (-75) (-75) (-75) (-75) (-75) (-75)
				(-75) (-75) (-75) (-75) (-75) (-75) (-75) (-75) (-75) (-75) (-75) (-75) (-75) (-75) (-75) (-75) (-75) (-75)
				(-75) (-75) (-75) (-75) (-75) (-75) (-75) (-75) (-75) (-75) (-75) (-75) (-75) (-75) (-75) (-75) (-75) (-75)
				(-75) (-75) (-75) (-75) (-75) (-75) (-75) (-75) (-75) (-75) (-75) (-75) (-75) (-75) (-75) (-75) (-75) (-75)
				(-75) (-75) (-75) (-75) (-75) (-75) (-75) (-75) (-75) (-75) (-75) (-75) (-75) (-75) (-75) (-75) (-75) (-75)
				(-75) (-75) (-75) (-75) (-75) (-75) (-75) (-75) (-75) (-75) (-75) (-75) (-75) (-75) (-75) (-75) (-75) (-75)
				(-75) (-75) (-75) (-75) (-75) (-75) (-75) (-75) (-75) (-75) (-75) (-75) (-75) (-75) (-75) (-75) (-75) (-75)
				(-75) (-75) (-75) (-75) (-75) (-75) (-75) (-75) (-75) (-75) (-75) (-75) (-75) (-75) (-75) (-75) (-75) (-75)
				(-75) (-75) (-75) (-75) (-75) (-75) (-75) (-75) (-75) (-75) (-75) (-75) (-75) (-75) (-75) (-75) (-75) (-75)
				(-75) (-75) (-75) (-75) (-75) (-75) (-75) (-75) (-75) (-75) (-75) (-75) (-75) (-75) (-75) (-75) (-75) (-75)
				(-75) (-75) (-75) (-75) (-75) (-75) (-75) (-75) (-75) (-75) (-75) (-75) (-75) (-75) (-75) (-75) (-75) (-75)
				(-75) (-75) (-75) (-75) (-75) (-75) (-75) (-75) (-75) (-75) (-75) (-75) (-75) (-75) (-75) (-75) (-75) (-75)
				(-75) (-75) (-75) (-75) (-75) (-75) (-75) (-75) (-75) (-75) (-75) (-75) (-75) (-75) (-75) (-75) (-75) (-75)
				(-75) (-75) (-75) (-75) (-75) (-75) (-75) (-75) (-75) (-75) (-75) (-75) (-75) (-75) (-75) (-75) (-75) (-75)
				(-75) (-75) (-75) (-75) (-75) (-75) (-75) (-75) (-75) (-75) (-75) (-75) (-75) (-75) (-75) (-75) (-75) (-75)
				(-75) (-75) (-75) (-75) (-75) (-75) (-75) (-75) (-75) (-75) (-75) (-75) (-75) (-75) (-75) (-75) (-75) (-75)
				(-75) (-75) (-75) (-75) (-75) (-75) (-75) (-75) (-75) (-75) (-75) (-75) (-75) (-75) (-75) (-75) (-75) (-75)
				(-75) (-75) (-75) (-75) (-75) (-75) (-75) (-75) (-75) (-75) (-75) (-75) (-75) (-75) (-75) (-75) (-75) (-75)
				(-75) (-75) (-75) (-75) (-75) (-75) (-75) (-75) (-75) (-75) (-75) (-75) (-75) (-75) (-75) (-75) (-75) (-75)
				(-75) (-75) (-75) (-75) (-75) (-75) (-75) (-75) (-75) (-75) (-75) (-75) (-75) (-75) (-75) (-75) (-75) (-75)
				(-75) (-75) (-75) (-75) (-75) (-75) (-75) (-75) (-75) (-75) (-75) (-75) (-75) (-75) (-75) (-75) (-75) (-75)
				(-75) (-75) (-75) (-75) (-75) (-75) (-75) (-75) (-75) (-75) (-75) (-75) (-75) (-75) (-75) (-75) (-75) (-75)
				(-75) (-75) (-75) (-75) (-75) (-75) (-75) (-75) (-75) (-75) (-75) (-75) (-75) (-75) (-75) (-75) (-75) (-75)
				(-75) (-75) (-75) (-75) (-75) (-75) (-75) (-75) (-75) (-75) (-75) (-75) (-75) (-75) (-75) (-75) (-75) (-75)
				(-75) (-75) (-75) (-75) (-75) (-75) (-75) (-75) (-75) (-75) (-75) (-75) (-75) (-75) (-75) (-75) (-75) (-75)
				(-75) (-75) (-75) (-75) (-75) (-75) (-75) (-75) (-75) (-75) (-75) (-75) (-75) (-75) (-75) (-75) (-75) (-75)
				(-75) (-75) (-75) (-75) (-75) (-75) (-75) (-75) (-75) (-75) (-75) (-75) (-75) (-75) (-75) (-75) (-75) (-75)
				(-75) (-75) (-75) (-75) (-75) (-75) (-75) (-75) (-75) (-75) (-75) (-75) (-75) (-75) (-75) (-75) (-75) (-75)
				(-75) (-75) (-75)>;

			PS_Config_Diff_Test_Frame = <50>;
		};
	};

	onewire_gpio: onewire_gpio {
		compatible = "xiaomi,onewire_gpio";
		label = "xm_onewire";
		xiaomi,version = <1>;
		xiaomi,ow_gpio = <&tlmm 11 0x00>;
		xiaomi,gpio_number = <11>;
		mi,onewire-gpio-cfg-addr = <0x0f10b000 0x4>;
		pinctrl-names = "onewire_active", "onewire_sleep";
		pinctrl-0 = <&onewire_gpio_active>;
		pinctrl-1 = <&onewire_gpio_sleep>;
		status = "ok";
	};

	maxim_ds28e16: maxim_ds28e16 {
		compatible = "maxim,ds28e16";
		label = "max_ds28e16";
		maxim,version = <1>;
		status = "ok";
	};

	gauguin_batterydata: qcom,battery-data {
		qcom,batt-id-range-pct = <15>;
		#include "qg-gauguin-cosmx-4820mah.dtsi"
		#include "qg-gauguin-sunwd-4820mah.dtsi"
	};

	testing_mode {
		compatible = "xiaomi,testing-mode";
		status-gpio = <&tlmm 84 0x00>;
		debounce-time = <30>;
		pinctrl-names = "default";
		pinctrl-0 = <&test_mode_irq>;
	};
};

&soc {
	fingerprint_goodix {
		compatible = "goodix,fingerprint";
		goodix,gpio-reset = <&tlmm 18 0x0>;
		goodix,gpio-irq = <&tlmm 17 0x0>;
		fp_vdd_vreg-supply = <&pm6350_l8>;
		status = "ok";
	};

	fingerprint_fpc {
               status = "ok";
               compatible = "fpc,fpc1020";
               fpc,gpio_rst    = <&tlmm 18 0x0>;
               fpc,gpio_irq    = <&tlmm 17 0x0>;
               pinctrl-names = "fpc1020_reset_reset",
                       "fpc1020_reset_active",
                       "fpc1020_irq_active";

               pinctrl-0 = <&msm_gpio_18>;
               pinctrl-1 = <&msm_gpio_18_output_high>;
               pinctrl-2 = <&msm_gpio_17>;

       };
};

&tlmm {
        /* GPIO_18 : FP_RESET_N */
        msm_gpio_18: msm_gpio_18 {
                mux {
                         pins = "gpio18";
                         function = "gpio";
                };

                config {
                        pins = "gpio18";
                        drive-strength = <2>;
                        bias-disable;
                        output-low;
                };
        };

        /* GPIO_18 : FP_RESET_N, state device active*/
        msm_gpio_18_output_high: msm_gpio_18_output_high {
                mux {
                        pins = "gpio18";
                        function = "gpio";
                };

                config {
                        pins = "gpio18";
                        drive-strength = <2>;
                        bias-disable;
                        output-high;
                };
        };

        /* GPIO_17 : FP_INT_N */
        msm_gpio_17: msm_gpio_17 {
                mux {
                        pins = "gpio17";
                        function = "gpio";
                };

                config {
                        pins = "gpio17";
                        drive-strength = <2>;
                        bias-pull-down;
                };
        };
};

&pm6350_l8 {
	qcom,init-voltage = <3000000>;
};

&qupv3_se9_spi {
	status = "ok";
	irled@0 {
		compatible = "ir-spi";
		reg = <0x0 0x0>;
		status = "ok";
		spi-max-frequency = <19200000>;
	};
};

&msm_notifier {
	panel = <&dsi_j17_36_02_0a_video
		 &dsi_j17_42_02_0b_video>;
};
